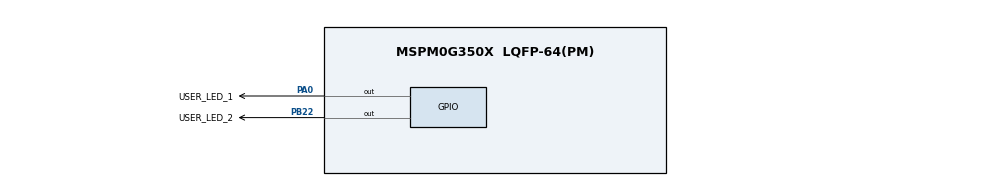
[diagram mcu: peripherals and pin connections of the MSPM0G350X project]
// @cliArgs --device "MSPM0G350X" --package "LQFP-64(PM)" --part "Default"
// @cliArgs --board /ti/boards/LP_MSPM0G3507 --rtos nortos

/**
 * Import the modules used in this configuration.
 */
const GPIO   = scripting.addModule("/ti/driverlib/GPIO", {}, false);
const GPIO1  = GPIO.addInstance();
const GPIO2  = GPIO.addInstance();
const SYSCTL = scripting.addModule("/ti/driverlib/SYSCTL");
const TIMER  = scripting.addModule("/ti/driverlib/TIMER", {}, false);
const TIMER1 = TIMER.addInstance();
const TIMER2 = TIMER.addInstance();

/**
 * Write custom configuration values to the imported modules.
 */
GPIO1.port                           = "PORTA";
GPIO1.$name                          = "GPIO_LEDS1";
GPIO1.associatedPins[0].$name        = "USER_LED_1";
GPIO1.associatedPins[0].assignedPin  = "0";
GPIO1.associatedPins[0].initialValue = "SET";
GPIO1.associatedPins[0].pin.$assign  = "PA0";

const Board           = scripting.addModule("/ti/driverlib/Board", {}, false);
Board.configureUnused = true;

GPIO2.port                          = "PORTB";
GPIO2.$name                         = "GPIO_LEDS2";
GPIO2.associatedPins[0].assignedPin = "22";
GPIO2.associatedPins[0].$name       = "USER_LED_2";
GPIO2.associatedPins[0].pin.$assign = "PB22";

SYSCTL.forceDefaultClkConfig = true;
SYSCTL.clockTreeEn  = true;

TIMER1.$name              = "TIMER_0";
TIMER1.timerMode          = "PERIODIC";
TIMER1.interrupts         = ["ZERO"];
TIMER1.timerClkSrc        = "LFCLK";
TIMER1.timerClkPrescale   = 33;
TIMER1.timerPeriod        = "1000 ms";
TIMER1.peripheral.$assign = "TIMG0";

TIMER2.$name              = "TIMER_1";
TIMER2.timerClkPrescale   = 256;
TIMER2.timerMode          = "PERIODIC";
TIMER2.timerPeriod        = "250 ms";
TIMER2.interrupts         = ["ZERO"];
TIMER2.peripheral.$assign = "TIMG8";
